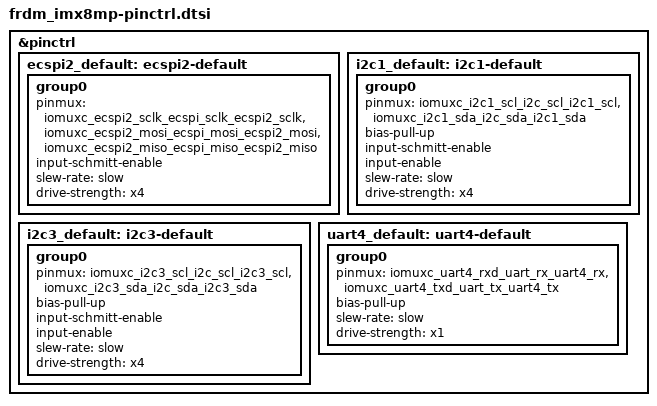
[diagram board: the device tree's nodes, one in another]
/* SPDX-License-Identifier: Apache-2.0 */
/* SPDX-FileCopyrightText: Copyright (c) 2026 Filip Stojanovic <filipembedded@gmail.com> */

#include <nxp/imx/pinctrl/mimx8ml8dvnlz-pinctrl.dtsi>

&pinctrl {
	ecspi2_default: ecspi2-default {
		group0 {
			pinmux = <&iomuxc_ecspi2_sclk_ecspi_sclk_ecspi2_sclk>,
				 <&iomuxc_ecspi2_mosi_ecspi_mosi_ecspi2_mosi>,
				 <&iomuxc_ecspi2_miso_ecspi_miso_ecspi2_miso>;
			input-schmitt-enable;
			slew-rate = "slow";
			drive-strength = "x4";
		};
	};

	i2c1_default: i2c1-default {
		group0 {
			pinmux = <&iomuxc_i2c1_scl_i2c_scl_i2c1_scl>,
				 <&iomuxc_i2c1_sda_i2c_sda_i2c1_sda>;
			bias-pull-up;
			input-schmitt-enable;
			input-enable;
			slew-rate = "slow";
			drive-strength = "x4";
		};
	};

	i2c3_default: i2c3-default {
		group0 {
			pinmux = <&iomuxc_i2c3_scl_i2c_scl_i2c3_scl>,
				 <&iomuxc_i2c3_sda_i2c_sda_i2c3_sda>;
			bias-pull-up;
			input-schmitt-enable;
			input-enable;
			slew-rate = "slow";
			drive-strength = "x4";
		};
	};

	uart4_default: uart4-default {
		group0 {
			pinmux = <&iomuxc_uart4_rxd_uart_rx_uart4_rx>,
				 <&iomuxc_uart4_txd_uart_tx_uart4_tx>;
			bias-pull-up;
			slew-rate = "slow";
			drive-strength = "x1";
		};
	};
};
